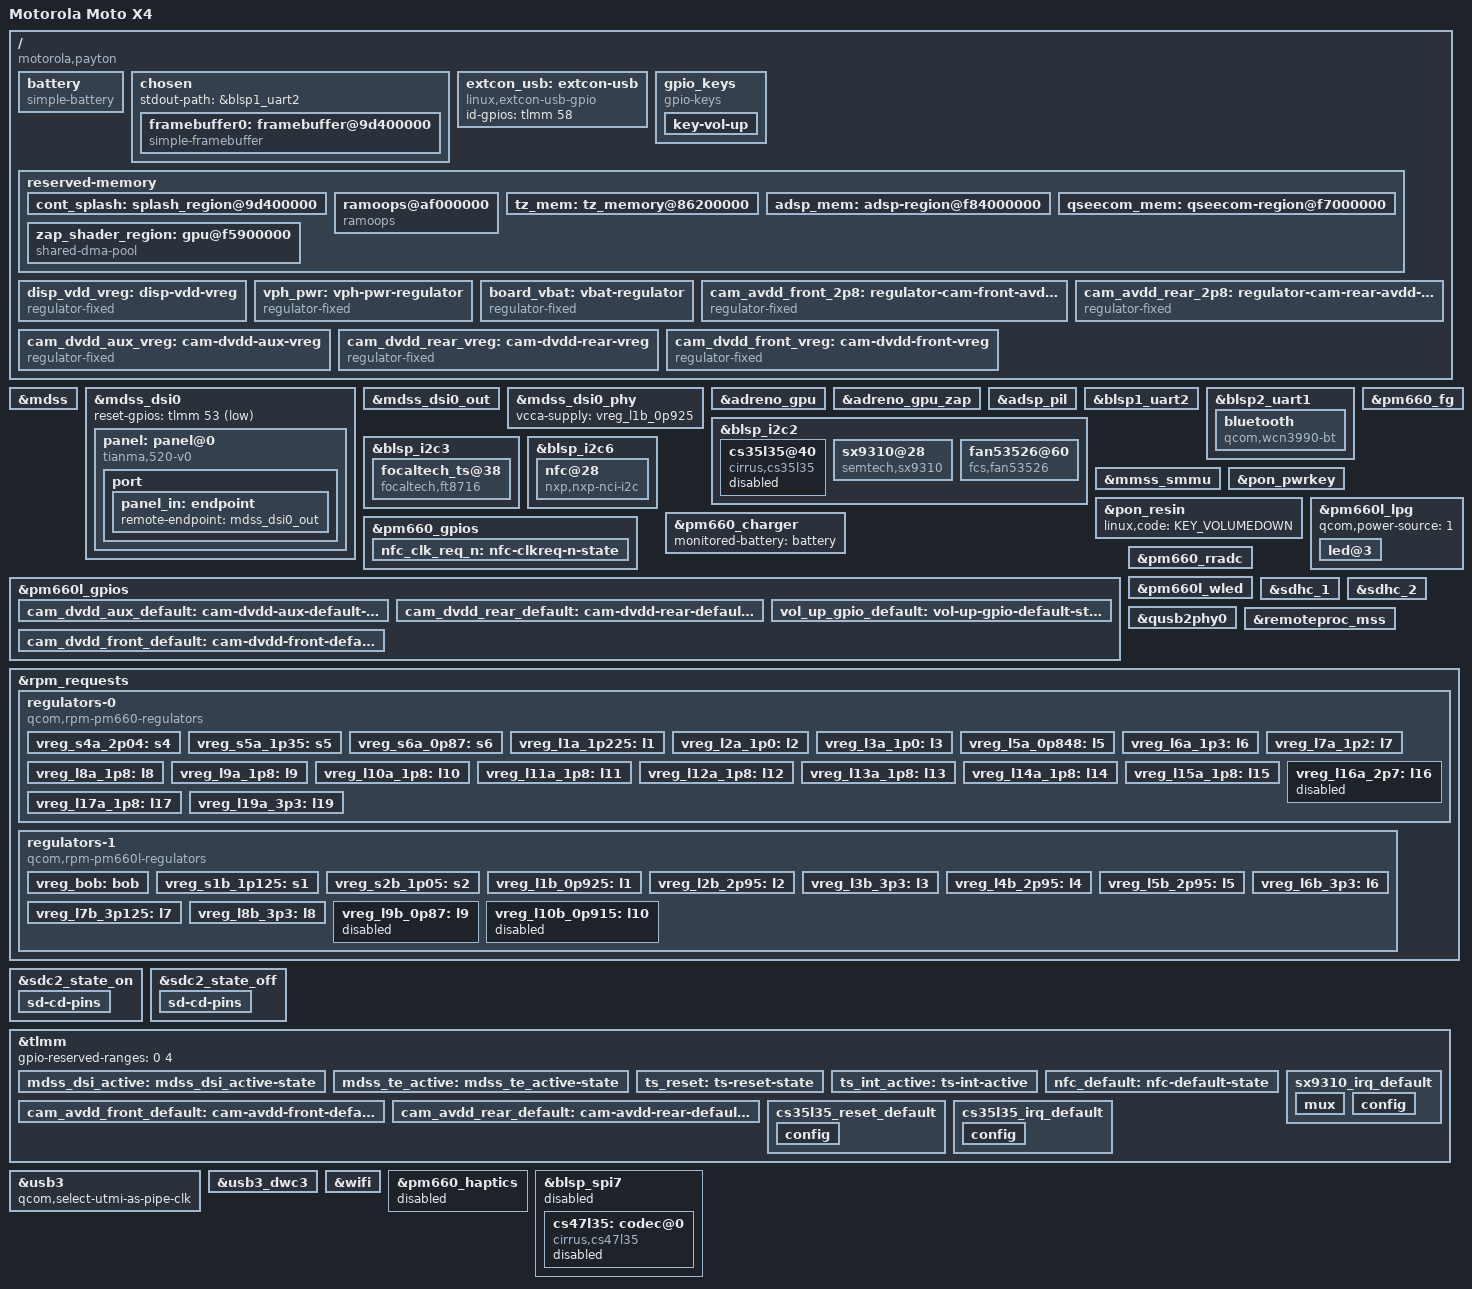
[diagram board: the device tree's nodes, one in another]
/dts-v1/;

#include "sdm630.dtsi"
#include "pm660.dtsi"
#include "pm660l.dtsi"
#include <dt-bindings/arm/qcom,ids.h>
#include <dt-bindings/input/input.h>
#include <dt-bindings/input/gpio-keys.h>
#include <dt-bindings/leds/common.h>
#include <dt-bindings/pinctrl/qcom,pmic-gpio.h>

/delete-node/ &adsp_mem;
/delete-node/ &qseecom_mem;
/delete-node/ &tz_mem;
/delete-node/ &zap_shader_region;

/ {
	model = "Motorola Moto X4";
	compatible = "motorola,payton", "qcom,sdm630";
	chassis-type = "handset";

	qcom,msm-id = <QCOM_ID_SDM630 0x0>;
	qcom,board-id = <0x41 0x81A0>;

	battery: battery {
		compatible = "simple-battery";

		charge-full-design-microamp-hours = <3000000>;
		voltage-min-design-microvolt = <3400000>;
		voltage-max-design-microvolt = <4400000>;
	};

	chosen {
		#address-cells = <2>;
		#size-cells = <2>;
		ranges;

		stdout-path = "&blsp1_uart2";
		//stdout-path = "framebuffer0";

		framebuffer0: framebuffer@9d400000 {
			compatible = "simple-framebuffer";
			reg = <0x0 0x9d400000 0x0 (1080 * 1920 * 4)>;
			status = "okay";
			width = <1080>;
			height = <1920>;
			stride = <(1080 * 4)>;
			format = "a8r8g8b8";

			/* Prevent unused clocks from being disabled; keep bootloader-enabled
	 		 * display stack (and framebuffer) working.
	 		 */
			assigned-clocks = <&mmcc MDSS_MDP_CLK>, <&mmcc MDSS_VSYNC_CLK>; /* from mdp */
			assigned-clock-rates = <300000000>, <19200000>;                 /* from mdp */
			clocks = <&mmcc MDSS_AHB_CLK>, /* from mdss & mdp */
				<&mmcc MDSS_AXI_CLK>,
				<&mmcc MDSS_VSYNC_CLK>,
				<&mmcc MDSS_MDP_CLK>,
				<&mmcc BYTE0_CLK_SRC>, /* from mdss_dsi0 */
				<&mmcc PCLK0_CLK_SRC>,
				<&mmcc MDSS_BYTE0_CLK>,
				<&mmcc MDSS_BYTE0_INTF_CLK>,
				<&mmcc MNOC_AHB_CLK>,
				<&mmcc MISC_AHB_CLK>,
				<&mmcc MDSS_PCLK0_CLK>,
				<&mmcc MDSS_ESC0_CLK>;
			/* Prevent unused power domains from being disabled (similar to clocks) */
			power-domains = <&rpmpd SDM660_VDDCX>, <&mmcc MDSS_GDSC>;

		};
	};

	/*
	 * Until we hook up type-c detection, we
	 * have to stick with this. But it works.
	 */
	extcon_usb: extcon-usb {
		compatible = "linux,extcon-usb-gpio";
		id-gpios = <&tlmm 58 GPIO_ACTIVE_HIGH>;
	};

	gpio_keys {
		status = "okay";
		compatible = "gpio-keys";
		label = "Volume up";
		pinctrl-names = "default";
		pinctrl-0 = <&vol_up_gpio_default>;

		key-vol-up {
			label = "Volume Up";
			gpios = <&pm660l_gpios 7 GPIO_ACTIVE_LOW>;
			linux,input-type = <EV_KEY>;
			linux,code = <KEY_VOLUMEUP>;
			debounce-interval = <15>;
		};
	};

	reserved-memory {
		cont_splash: splash_region@9d400000 {
			reg = <0x0 0x9d400000 0x0 0x23ff000>;
			no-map;
		};

		ramoops@af000000 {
			compatible = "ramoops";
			reg = <0x0 0xaf000000 0x0 0xc0000>;
			console-size = <0x40000>;
			record-size = <0x3f800>;
			ftrace-size = <0x0>;
			pmsg-size = <0x40000>;
		};

		tz_mem: tz_memory@86200000 {
			reg = <0x0 0x86200000 0x0 0x2D00000>;
			no-map;
		};

		adsp_mem: adsp-region@f84000000 {
			reg = <0x0 0xf8400000 0x0 0x800000>;
			no-map;
		};

		qseecom_mem: qseecom-region@f7000000 {
			reg = <0x0 0xf7000000 0x0 0x1400000>;
			no-map;
		};

		zap_shader_region: gpu@f5900000 {
			compatible = "shared-dma-pool";
			reg = <0x0 0xf5900000 0x0 0x2000>;
			no-map;
		};
	};

	disp_vdd_vreg: disp-vdd-vreg {
		compatible = "regulator-fixed";
		regulator-name = "display-vdd";

		regulator-min-microvolt = <1800000>;
		regulator-max-microvolt = <1800000>;
		regulator-always-on;
		regulator-boot-on;
		vin-supply = <&vreg_l11a_1p8>;
	};

	vph_pwr: vph-pwr-regulator {
		compatible = "regulator-fixed";
		regulator-name = "vph_pwr";
		regulator-min-microvolt = <3700000>;
		regulator-max-microvolt = <3700000>;

		regulator-always-on;
		regulator-boot-on;
	};

	board_vbat: vbat-regulator {
		compatible = "regulator-fixed";
		regulator-name = "VBAT";

		regulator-min-microvolt = <4000000>;
		regulator-max-microvolt = <4000000>;
		regulator-always-on;
		regulator-boot-on;
	};

	cam_avdd_front_2p8: regulator-cam-front-avdd-2p8 {
		compatible = "regulator-fixed";
		regulator-name = "cam_avdd_front_2p8";
		regulator-min-microvolt = <2800000>;
		regulator-max-microvolt = <2800000>;
		gpio = <&tlmm 49 GPIO_ACTIVE_HIGH>;
		enable-active-high;
		startup-delay-us = <5000>;
		pinctrl-names = "default";
		pinctrl-0 = <&cam_avdd_front_default>;
		vin-supply = <&board_vbat>;
	};

	cam_avdd_rear_2p8: regulator-cam-rear-avdd-2p8 {
		compatible = "regulator-fixed";
		regulator-name = "cam_avdd_rear_2p8";
		regulator-min-microvolt = <2800000>;
		regulator-max-microvolt = <2800000>;
		gpio = <&tlmm 51 GPIO_ACTIVE_HIGH>;
		enable-active-high;
		startup-delay-us = <0>;
		pinctrl-names = "default";
		pinctrl-0 = <&cam_avdd_rear_default>;
		vin-supply = <&board_vbat>;
	};

	cam_dvdd_aux_vreg: cam-dvdd-aux-vreg {
		compatible = "regulator-fixed";
		regulator-name = "cam-dvdd-aux-vreg";

		regulator-min-microvolt = <1200000>;
		regulator-max-microvolt = <1200000>;
		startup-delay-us = <0>;
		enable-active-high;
		gpio = <&pm660l_gpios 3 GPIO_ACTIVE_HIGH>;
		pinctrl-names = "default";
		pinctrl-0 = <&cam_dvdd_aux_default>;
		vin-supply = <&vreg_s5a_1p35>;
	};

	cam_dvdd_rear_vreg: cam-dvdd-rear-vreg {
		compatible = "regulator-fixed";
		regulator-name = "cam-dvdd-rear-vreg";

		regulator-min-microvolt = <1050000>;
		regulator-max-microvolt = <1050000>;
		startup-delay-us = <0>;
		enable-active-high;
		gpio = <&pm660l_gpios 4 GPIO_ACTIVE_HIGH>;
		pinctrl-names = "default";
		pinctrl-0 = <&cam_dvdd_rear_default>;
		vin-supply = <&vreg_s5a_1p35>;
	};

	cam_dvdd_front_vreg: cam-dvdd-front-vreg {
		compatible = "regulator-fixed";
		regulator-name = "cam-dvdd-front-vreg";

		regulator-min-microvolt = <1200000>;
		regulator-max-microvolt = <1200000>;
		startup-delay-us = <0>;
		enable-active-high;
		gpio = <&pm660l_gpios 8 GPIO_ACTIVE_HIGH>;
		pinctrl-names = "default";
		pinctrl-0 = <&cam_dvdd_front_default>;
		vin-supply = <&vreg_s5a_1p35>;
	};
};

&mdss {
	status = "okay";
};

&mdss_dsi0 {
	status = "okay";

        reset-gpios = <&tlmm 53 GPIO_ACTIVE_LOW>;

	#address-cells = <1>;
	#size-cells = <0>;

        panel: panel@0 {
                reg = <0>;
                compatible = "tianma,520-v0";

		vddio-supply = <&disp_vdd_vreg>;

         	backlight = <&pm660l_wled>;
                reset-gpios = <&tlmm 53 GPIO_ACTIVE_LOW>;

		pinctrl-names = "default";
		pinctrl-0 = <&mdss_dsi_active &mdss_te_active>;

                port {
                        panel_in: endpoint {
                                remote-endpoint = <&mdss_dsi0_out>;
                        };
                };
        };
};

&mdss_dsi0_out {
        data-lanes = <0 1 2 3>;
        remote-endpoint = <&panel_in>;
};

&mdss_dsi0_phy {
	vcca-supply = <&vreg_l1b_0p925>;
	status = "okay";
};

&adreno_gpu {
	status = "okay";
};

&adreno_gpu_zap {
	memory-region = <&zap_shader_region>;
	firmware-name = "qcom/sdm630/motorola/payton/a508_zap.mdt";
};

&adsp_pil {
	firmware-name = "qcom/sdm630/motorola/payton/adsp.mdt";
	status = "okay";
};

&blsp1_uart2 {
	status = "okay";
};

&blsp2_uart1 {
	status = "okay";

	/* HCI Bluetooth */
	bluetooth {
		compatible = "qcom,wcn3990-bt";
		vddxo-supply = <&vreg_l9a_1p8>;
		vddrf-supply = <&vreg_l6a_1p3>;
		vddch0-supply = <&vreg_l19a_3p3>;
		vddio-supply = <&vreg_l13a_1p8>;
		max-speed = <3200000>;
	};
};

&blsp_i2c2 {
	status = "okay";
	/* semtech,sx9310 @ 0x28, capsense? */
	cs35l35@40 {
		compatible = "cirrus,cs35l35";
		reg = <0x40>;
		status = "disabled";

		VA-supply = <&vreg_l13a_1p8>;
		VP-supply = <&board_vbat>;

		reset-gpios = <&tlmm 63 0>;
		interrupt-parent = <&tlmm>;
		interrupts = <76 IRQ_TYPE_LEVEL_LOW>;
		/* cirrus,boost-ctl-millivolt = <9000>; */
		cirrus,boost-ind-nanohenry = <1000>;

		pinctrl-names = "default";
		pinctrl-0 = <&cs35l35_reset_default &cs35l35_irq_default>;

	};
	sx9310@28 {
		compatible = "semtech,sx9310";
		reg = <0x28>;
		status = "okay";
		interrupt-parent = <&tlmm>;
		interrupts = <75 IRQ_TYPE_LEVEL_LOW>;
		vdd-supply = <&vreg_l8b_3p3>;
		svdd-supply = <&vreg_l13a_1p8>;
		#io-channel-cells = <1>;
		semtech,cs0-ground;
		semtech,combined-sensors = <2>;
		semtech,resolution = "fine";
		semtech,startup-sensor = <2>;
		semtech,proxraw-strength = <4>;
		semtech,avg-pos-strength = <256>;

		pinctrl-names = "default";
		pinctrl-0 = <&sx9310_irq_default>;
	};
	fan53526@60 {
		compatible = "fcs,fan53526";
		reg = <0x60>;
		regulator-name = "VREG_LP4X_0P6";
		regulator-min-microvolt = <600000>;
		regulator-max-microvolt = <600000>;
		vin-supply = <&board_vbat>;
		fcs,suspend-voltage-selector = <1>;
		regulator-always-on;
		regulator-boot-on;
	};
};

&blsp_i2c3 {
	status = "okay";

	focaltech_ts@38 {
		compatible = "focaltech,ft8716";
		reg = <0x38>;
		
		pinctrl-names = "default";
		pinctrl-0 = <&ts_int_active &ts_reset>;

		interrupt-parent = <&tlmm>;
		interrupts = <67 IRQ_TYPE_EDGE_FALLING>;

		reset-gpios = <&tlmm 66 GPIO_ACTIVE_LOW>;


	};

};

&blsp_i2c6 {
	status = "okay";

	nfc@28 {
		compatible = "nxp,nxp-nci-i2c";
		reg = <0x28>;

		// TODO: Double check the interrupt and pinctrls for NFC
		interrupt-parent = <&tlmm>;
		interrupts = <40 IRQ_TYPE_EDGE_RISING>;

		enable-gpios = <&tlmm 28 GPIO_ACTIVE_HIGH>;
		firmware-gpios = <&tlmm 30 GPIO_ACTIVE_HIGH>;


		pinctrl-names = "default";
		pinctrl-0 = <&nfc_default>;
	};
};

&mmss_smmu {
	status = "okay";
};

&pon_pwrkey {
	status = "okay";
};

&pon_resin {
	status = "okay";

	linux,code = <KEY_VOLUMEDOWN>;
};

&pm660_charger {
	monitored-battery = <&battery>;

	status = "okay";
};

&pm660_fg {
	monitored-battery = <&battery>;
	power-supplies = <&pm660_charger>;

	status = "okay";
};


&pm660_gpios {
        nfc_clk_req_n: nfc-clkreq-n-state {
                pins = "gpio4";
                function = PMIC_GPIO_FUNC_NORMAL;
                bias-disable;
                input-enable;
                power-source = <1>;
        };
};

&pm660l_gpios {
        cam_dvdd_aux_default: cam-dvdd-aux-default-state {
                pins = "gpio3";
                output-low;
                power-source = <0>;
                function = "normal";
        };

        cam_dvdd_rear_default: cam-dvdd-rear-default-state {
                pins = "gpio4";
                function = "normal";
                output-low;
                power-source = <0>;
        };

        vol_up_gpio_default: vol-up-gpio-default-state {
                pins = "gpio7";
                function = "normal";
                bias-pull-up;
                input-enable;
                qcom,drive-strength = <PMIC_GPIO_STRENGTH_NO>;
        };

        cam_dvdd_front_default: cam-dvdd-front-default-state {
                pins = "gpio8";
                function = "normal";
                output-low;
                power-source = <0>;
	};
};

&pm660l_lpg {
	status = "okay";

	qcom,power-source = <1>;

	#address-cells = <1>;
	#size-cells = <0>;

	led@3 {
		reg = <3>;
		color = <LED_COLOR_ID_WHITE>;
		function = LED_FUNCTION_STATUS;
	};
};

&pm660_rradc {
	status = "okay";
};

&pm660l_wled {
	default-brightness = <512>;

	status = "okay";

	/* qcom,num-strings = <3>; */
	qcom,enabled-strings = <0 1 2>;
	qcom,cabc;
	qcom,cabc-sel = <3>;
	qcom,ext-gen;
};

&sdhc_1 {
	bus-width = <8>;
	non-removable;
	mmc-ddr-1_8v;    
	mmc-hs200-1_8v;  
	mmc-hs400-1_8v; 
	vmmc-supply = <&vreg_l4b_2p95>;
	vqmmc-supply = <&vreg_l8a_1p8>;
	
	status = "okay";
};

&sdhc_2 {
	cd-gpios = <&tlmm 54 GPIO_ACTIVE_HIGH>;

	vmmc-supply = <&vreg_l5b_2p95>;
	vqmmc-supply = <&vreg_l2b_2p95>;

	status = "okay";
};

&qusb2phy0 {
	vdd-supply = <&vreg_l1b_0p925>;
	vdda-pll-supply = <&vreg_l10a_1p8>;
	vdda-phy-dpdm-supply = <&vreg_l7b_3p125>;

	status = "okay";
};

&remoteproc_mss {
	firmware-name = "qcom/sdm630/motorola/payton/mba.mbn", "qcom/sdm630/motorola/payton/modem.mdt";
	status = "okay";
};

// TODO: Double check regulators
&rpm_requests {
	regulators-0 {
		compatible = "qcom,rpm-pm660-regulators";

		vdd_s1-supply = <&vph_pwr>;
		vdd_s2-supply = <&vph_pwr>;
		vdd_s3-supply = <&vph_pwr>;
		vdd_s4-supply = <&vph_pwr>;
		vdd_s5-supply = <&vph_pwr>;
		vdd_s6-supply = <&vph_pwr>;

		vdd_l1_l6_l7-supply = <&vreg_s5a_1p35>;
		vdd_l2_l3-supply = <&vreg_s2b_1p05>;
		vdd_l5-supply = <&vreg_s2b_1p05>;
		vdd_l8_l9_l10_l11_l12_l13_l14-supply = <&vreg_s4a_2p04>;
		vdd_l15_l16_l17_l18_l19-supply = <&vreg_bob>;

		/*
		 * S1A (FTAPC0), S2A (FTAPC1), S3A (HFAPC1) are managed
		 * by the Core Power Reduction hardened (CPRh) and the
		 * Operating State Manager (OSM) HW automatically.
		 */

		vreg_s4a_2p04: s4 {
			regulator-min-microvolt = <1805000>;
			regulator-max-microvolt = <2040000>;
			regulator-enable-ramp-delay = <200>;
			regulator-always-on;
		};

		vreg_s5a_1p35: s5 {
			regulator-min-microvolt = <1224000>;
			regulator-max-microvolt = <1350000>;
			regulator-enable-ramp-delay = <200>;
		};

		vreg_s6a_0p87: s6 {
			regulator-min-microvolt = <504000>;
			regulator-max-microvolt = <992000>;
			regulator-enable-ramp-delay = <150>;
		};

		/* LDOs */
		vreg_l1a_1p225: l1 {
			regulator-min-microvolt = <1150000>;
			regulator-max-microvolt = <1250000>;
			regulator-enable-ramp-delay = <250>;
			regulator-allow-set-load;
		};

		vreg_l2a_1p0: l2 {
			regulator-min-microvolt = <950000>;
			regulator-max-microvolt = <1010000>;
			regulator-enable-ramp-delay = <250>;
		};

		vreg_l3a_1p0: l3 {
			regulator-min-microvolt = <950000>;
			regulator-max-microvolt = <1010000>;
			regulator-enable-ramp-delay = <250>;
		};

		vreg_l5a_0p848: l5 {
			regulator-min-microvolt = <525000>;
			regulator-max-microvolt = <950000>;
			regulator-enable-ramp-delay = <250>;
		};

		vreg_l6a_1p3: l6 {
			regulator-min-microvolt = <1200000>;
			regulator-max-microvolt = <1370000>;
			regulator-allow-set-load;
			regulator-enable-ramp-delay = <250>;
		};

		vreg_l7a_1p2: l7 {
			regulator-min-microvolt = <1200000>;
			regulator-max-microvolt = <1200000>;
			regulator-enable-ramp-delay = <250>;
		};

		vreg_l8a_1p8: l8 {
			regulator-min-microvolt = <1750000>;
			regulator-max-microvolt = <1900000>;
			regulator-enable-ramp-delay = <250>;
			regulator-system-load = <325000>;
			regulator-allow-set-load;
		};

		vreg_l9a_1p8: l9 {
			regulator-min-microvolt = <1750000>;
			regulator-max-microvolt = <1900000>;
			regulator-enable-ramp-delay = <250>;
			regulator-allow-set-load;
		};

		vreg_l10a_1p8: l10 {
			regulator-min-microvolt = <1780000>;
			regulator-max-microvolt = <1950000>;
			regulator-enable-ramp-delay = <250>;
			regulator-allow-set-load;
		};

		vreg_l11a_1p8: l11 {
			regulator-min-microvolt = <1780000>;
			regulator-max-microvolt = <1950000>;
			regulator-enable-ramp-delay = <250>;
		};

		vreg_l12a_1p8: l12 {
			regulator-min-microvolt = <1780000>;
			regulator-max-microvolt = <1950000>;
			regulator-enable-ramp-delay = <250>;
		};

		/* This gives power to the LPDDR4: never turn it off! */
		vreg_l13a_1p8: l13 {
			regulator-min-microvolt = <1780000>;
			regulator-max-microvolt = <1950000>;
			regulator-enable-ramp-delay = <250>;
			regulator-boot-on;
			regulator-always-on;
		};

		vreg_l14a_1p8: l14 {
			regulator-min-microvolt = <1710000>;
			regulator-max-microvolt = <1900000>;
			regulator-enable-ramp-delay = <250>;
		};

		vreg_l15a_1p8: l15 {
			regulator-name = "vreg_l15a_uim1";
			regulator-min-microvolt = <1650000>;
			regulator-max-microvolt = <2950000>;
			regulator-enable-ramp-delay = <250>;
		};

		vreg_l16a_2p7: l16 {
			/* Unused */
			status = "disabled";

			regulator-name = "vreg_l16a_2p7";
			regulator-min-microvolt = <2700000>;
			regulator-max-microvolt = <2700000>;
			regulator-enable-ramp-delay = <250>;
		};

		vreg_l17a_1p8: l17 {
			regulator-min-microvolt = <1650000>;
			regulator-max-microvolt = <2950000>;
			regulator-enable-ramp-delay = <250>;
		};

		vreg_l19a_3p3: l19 {
			regulator-min-microvolt = <3200000>;
			regulator-max-microvolt = <3400000>;
			regulator-enable-ramp-delay = <250>;
			regulator-allow-set-load;
		};
	};

	regulators-1 {
		compatible = "qcom,rpm-pm660l-regulators";

		vdd_s1-supply = <&vph_pwr>;
		vdd_s2-supply = <&vph_pwr>;
		vdd_s3_s4-supply = <&vph_pwr>;
		vdd_s5-supply = <&vph_pwr>;
		vdd_s6-supply = <&vph_pwr>;

		vdd_l1_l9_l10-supply = <&vreg_s2b_1p05>;
		vdd_l2-supply = <&vreg_bob>;
		vdd_l3_l5_l7_l8-supply = <&vreg_bob>;
		vdd_l4_l6-supply = <&vreg_bob>;
		vdd_bob-supply = <&vph_pwr>;

		vreg_bob: bob {
			regulator-min-microvolt = <3300000>;
			regulator-max-microvolt = <3600000>;
			regulator-enable-ramp-delay = <500>;
		};

		vreg_s1b_1p125: s1 {
			regulator-min-microvolt = <1125000>;
			regulator-max-microvolt = <1125000>;
			regulator-enable-ramp-delay = <200>;
		};

		vreg_s2b_1p05: s2 {
			regulator-min-microvolt = <1050000>;
			regulator-max-microvolt = <1050000>;
			regulator-enable-ramp-delay = <200>;
		};

		/* LDOs */
		vreg_l1b_0p925: l1 {
			regulator-min-microvolt = <800000>;
			regulator-max-microvolt = <925000>;
			regulator-enable-ramp-delay = <250>;
			regulator-allow-set-load;
		};

		/* SDHCI 3.3V signal doesn't seem to be supported. */
		vreg_l2b_2p95: l2 {
			regulator-min-microvolt = <1648000>;
			regulator-max-microvolt = <2696000>;
			regulator-enable-ramp-delay = <250>;
			regulator-allow-set-load;
		};

		vreg_l3b_3p3: l3 {
			regulator-min-microvolt = <1710000>;
			regulator-max-microvolt = <3600000>;
			regulator-enable-ramp-delay = <250>;
			regulator-allow-set-load;
			regulator-always-on;
		};

		vreg_l4b_2p95: l4 {
			regulator-min-microvolt = <1700000>;
			regulator-max-microvolt = <2950000>;
			regulator-enable-ramp-delay = <250>;

			regulator-min-microamp = <200>;
			regulator-max-microamp = <600000>;
			regulator-system-load = <570000>;
			regulator-allow-set-load;
		};

		/*
		 * Downstream specifies a range of 1721-3600mV,
		 * but the only assigned consumers are SDHCI2 VMMC
		 * and Coresight QPDI that both request pinned 2.95V.
		 * Tighten the range to 1.8-3.328 (closest to 3.3) to
		 * make the mmc driver happy.
		 */
		vreg_l5b_2p95: l5 {
			regulator-min-microvolt = <1800000>;
			regulator-max-microvolt = <3328000>;
			regulator-enable-ramp-delay = <250>;
			regulator-allow-set-load;
		};

		vreg_l6b_3p3: l6 {
			regulator-min-microvolt = <3000000>;
			regulator-max-microvolt = <3000000>;
			regulator-enable-ramp-delay = <250>;
			regulator-ramp-delay = <0>;
		};

		vreg_l7b_3p125: l7 {
			regulator-min-microvolt = <2700000>;
			regulator-max-microvolt = <3125000>;
			regulator-enable-ramp-delay = <250>;
		};

		vreg_l8b_3p3: l8 {
			regulator-min-microvolt = <3200000>;
			regulator-max-microvolt = <3400000>;
			regulator-enable-ramp-delay = <250>;
		};

		vreg_l9b_0p87: l9 {
			/* Unused */
			status = "disabled";
		};

		vreg_l10b_0p915: l10 {
			/* Unused */
			status = "disabled";
		};
	};
};

&sdc2_state_on {
	sd-cd-pins {
		pins = "gpio54";
		function = "gpio";
		bias-pull-up;
		drive-strength = <2>;
	};
};

&sdc2_state_off {
	sd-cd-pins {
		pins = "gpio54";
		function = "gpio";
		bias-disable;
		drive-strength = <2>;
	};
};

&tlmm {
	gpio-reserved-ranges = <0 4>;

	mdss_dsi_active: mdss_dsi_active-state {
		pins = "gpio53";
		function = "gpio";
		drive-strength = <8>;
		bias-disable;
	};

	mdss_te_active: mdss_te_active-state {
		pins = "gpio59";
		function = "mdp_vsync";
		drive-strength = <2>;
		bias-pull-down;
	};

	ts_reset: ts-reset-state {
		pins = "gpio66";
		function = "gpio";
		drive-strength = <8>;
		bias-disable;
	};

	ts_int_active: ts-int-active {
		pins = "gpio67";
		function = "gpio";
		drive-strength = <16>;
		bias-pull-up;
	};

	nfc_default: nfc-default-state {
		pins = "gpio29", "gpio30", "gpio31";
		function = "gpio";
		drive-strength = <2>;
		bias-pull-up;
	};

	cam_avdd_front_default: cam-avdd-front-default-state {
		pins = "gpio49";
		function = "gpio";
		bias-disable;
		drive-strength = <2>;
	};

	cam_avdd_rear_default: cam-avdd-rear-default-state {
		pins = "gpio51";
		function = "gpio";
		bias-disable;
		drive-strength = <2>;
	};

	sx9310_irq_default: sx9310_irq_default {
		mux {
			pins = "gpio75";
			function = "gpio";
		};

		config {
			pins = "gpio75";
			drive-strength = <2>;
			bias-pull-up;
		};
	};

	cs35l35_reset_default: cs35l35_reset_default {
		config {
			pins = "gpio63";
			output-low;
			bias-pull-up;
			drive-strength = <2>;
		};
	};
	cs35l35_irq_default: cs35l35_irq_default {
		config {
			pins = "gpio76";
			drive-strength = <2>;
			bias-pull-up;
		};
	};

};


&usb3 {
	qcom,select-utmi-as-pipe-clk;

	status = "okay";
};

&usb3_dwc3 {
	maximum-speed = "high-speed";
	phys = <&qusb2phy0>;
	phy-names = "usb2-phy";

	usb-role-switch;
	dr_mode = "otg";
	//dr_mode = "peripheral";
	extcon = <&extcon_usb>;
};

&wifi {
	vdd-0.8-cx-mx-supply = <&vreg_l5a_0p848>;
	vdd-1.8-xo-supply = <&vreg_l9a_1p8>;
	vdd-1.3-rfa-supply = <&vreg_l6a_1p3>;
	vdd-3.3-ch0-supply = <&vreg_l19a_3p3>;
	vdd-3.3-ch1-supply = <&vreg_l19a_3p3>;

	status = "okay";
};

&pm660_haptics {
	status = "disabled";

	qcom,actuator-type = <HAP_TYPE_ERM>;
	qcom,play-mode = <HAP_PLAY_DIRECT>;
};

&blsp_spi7 {
	status = "disabled";
};

&blsp_spi7 {
	status = "disabled";
	cs47l35: codec@0 {
		status = "disabled";
		compatible = "cirrus,cs47l35";
		spi-max-frequency = <26000000>;
		reg = <0x00>;

		interrupt-parent = <&tlmm>;
		interrupts = <21 IRQ_TYPE_LEVEL_LOW>;

		reset-gpios = <&tlmm 55 GPIO_ACTIVE_LOW>;

		AVDD-supply = <&vreg_l13a_1p8>;
		DBVDD1-supply = <&vreg_l13a_1p8>;
		DBVDD2-supply = <&vreg_l13a_1p8>;
		CPVDD-supply = <&vreg_l13a_1p8>;
		CPVDD1-supply = <&vreg_l13a_1p8>;
		CPVDD2-supply = <&vreg_l14a_1p8>;
		DCVDD-supply = <&vreg_l13a_1p8>;
		SPKVDD-supply = <&board_vbat>;

		interrupt-controller;
		#interrupt-cells = <2>;

		gpio-controller;
		#gpio-cells = <2>;

	};
};
